# STM32H7S7xx register map
File version: 1.0
Registers are 32-bit, read-write, reset 0x0 unless marked. A register's access mark holds for its fields unless they carry their own. Offsets are from the block's base; [hi:lo] are bit positions; {n}, {i} and the like mark numbered series; 'fields as' and 'values as' point back to an identical list.

## TIM12 — TIM
Base 0x40001800
Same registers: TIM9 0x42004C00
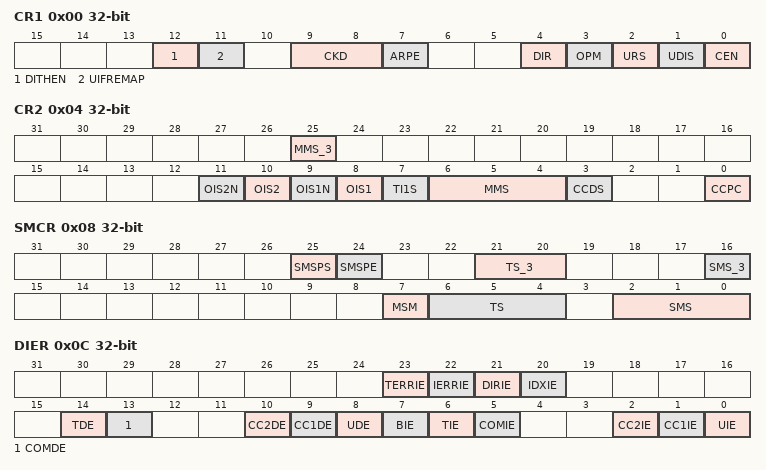
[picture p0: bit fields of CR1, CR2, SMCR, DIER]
0x00 CR1 — TIM control register 1
  [12] DITHEN — Dithering enable
  [11] UIFREMAP — Update interrupt flag remap
  [9:8] CKD — CKD[1:0] bits (clock division)
    0=DIV1 (tDTS=tCK_INT); 1=DIV2 (tDTS=2*tCK_INT); 2=DIV4 (tDTS=4*tCK_INT)
  [7] ARPE — Auto-reload preload enable
  [4] DIR — Direction
    0=UP (Timer counter counts up); 1=DOWN (Timer counter counts down)
  [3] OPM — One pulse mode
    1=SINGLE (Counter stops counting at the next update event); 0=REPETITIVE (Counter is not stopped at update event)
  [2] URS — Update request source
    0=REGULAR (Counter overflow/underflow, Setting the UG bit or Update generation through the slave mode controller generates an update request); 1=COUNTER (Only counter overflow/underflow generates an update request)
  [1] UDIS — Update disable
  [0] CEN — Counter enable
0x04 CR2 — TIM control register 2
  [25] MMS_3 — MMS[3:0] bits (Master Mode Selection)
  [11] OIS2N — Output Idle state 2 (OC2N output)
  [10] OIS2 — Output Idle state 2 (OC2 output)
  [9] OIS1N — Output Idle state 1 (OC1N output)
  [8] OIS1 — Output Idle state 1 (OC1 output)
  [7] TI1S — TI1 Selection
  [6:4] MMS — MMS[3:0] bits (Master Mode Selection)
  [3] CCDS — Capture/Compare DMA Selection
    0=CC (CCx DMA request sent when CCx event occurs); 1=UPDATE (CCx DMA requests sent when update event occurs)
  [0] CCPC — Capture/Compare Preloaded Control
0x08 SMCR — TIM slave mode control register
  [25] SMSPS — SMS preload source
    0=TIMUPDATE (The SMS preload transfer is triggered by the Timer's Update event); 1=INDEX (The SMS preload transfer is triggered by the Index event)
  [24] SMSPE — SMS preload enable
  [21:20] TS_3 — TS[2:0] bits (Trigger selection)
  [16] SMS_3 — SMS[2:0] bits (Slave mode selection)
  [7] MSM — Master/slave mode
  [6:4] TS — TS[2:0] bits (Trigger selection)
  [2:0] SMS — SMS[2:0] bits (Slave mode selection)
0x0C DIER — TIM DMA/interrupt enable register
  [23] TERRIE — Encoder transition error enable
  [22] IERRIE — Encoder index error enable
  [21] DIRIE — Encoder direction change interrupt enable
  [20] IDXIE — Encoder index interrupt enable
  [14] TDE — Trigger DMA request enable
  [13] COMDE — COM DMA request enable
  [10] CC2DE — Capture/Compare 2 DMA request enable
  [9] CC1DE — Capture/Compare 1 DMA request enable
  [8] UDE — Update DMA request enable
  [7] BIE — Break interrupt enable
  [6] TIE — Trigger interrupt enable
  [5] COMIE — COM interrupt enable
  [2] CC2IE — Capture/Compare 2 interrupt enable
  [1] CC1IE — Capture/Compare 1 interrupt enable
  [0] UIE — Update interrupt enable
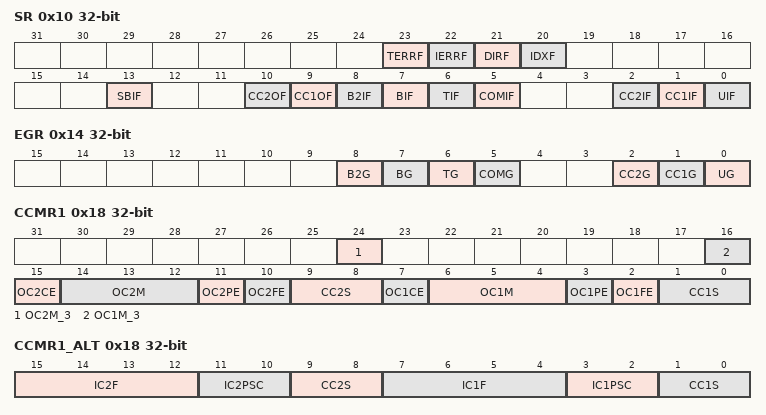
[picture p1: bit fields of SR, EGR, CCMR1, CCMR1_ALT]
0x10 SR — TIM status register
  [23] TERRF — Encoder transition error flag
  [22] IERRF — Encoder index error flag
  [21] DIRF — Encoder direction change interrupt flag
  [20] IDXF — Encoder index interrupt flag
  [13] SBIF — System Break interrupt Flag
  [10] CC2OF — Capture/Compare 2 Overcapture Flag
  [9] CC1OF — Capture/Compare 1 Overcapture Flag
  [8] B2IF — Break 2 interrupt Flag
  [7] BIF — Break interrupt Flag
  [6] TIF — Trigger interrupt Flag
  [5] COMIF — COM interrupt Flag
  [2] CC2IF — Capture/Compare 2 interrupt Flag
  [1] CC1IF — Capture/Compare 1 interrupt Flag
  [0] UIF — Update interrupt Flag
0x14 EGR — TIM event generation register
  [8] B2G — Break 2 Generation
  [7] BG — Break Generation
  [6] TG — Trigger Generation
  [5] COMG — Capture/Compare Control Update Generation
  [2] CC2G — Capture/Compare 2 Generation
  [1] CC1G — Capture/Compare 1 Generation
  [0] UG — Update Generation
0x18 CCMR1 — TIM capture/compare mode register 1
  [24] OC2M_3 — OC2M[2:0] bits (Output Compare 2 Mode)
  [16] OC1M_3 — OC1M[2:0] bits (Output Compare 1 Mode)
  [15] OC2CE — Output Compare 2 Clear Enable
  [14:12] OC2M — OC2M[2:0] bits (Output Compare 2 Mode)
  [11] OC2PE — Output Compare 2 Preload enable
  [10] OC2FE — Output Compare 2 Fast enable
  [9:8] CC2S — CC2S[1:0] bits (Capture/Compare 2 Selection)
  [7] OC1CE — Output Compare 1 Clear Enable
  [6:4] OC1M — OC1M[2:0] bits (Output Compare 1 Mode)
  [3] OC1PE — Output Compare 1 Preload enable
  [2] OC1FE — Output Compare 1 Fast enable
  [1:0] CC1S — CC1S[1:0] bits (Capture/Compare 1 Selection)
0x18 CCMR1_ALT (alternate view of CCMR1) — TIM capture/compare mode register 1
  [15:12] IC2F — IC2F[3:0] bits (Input Capture 2 Filter)
  [11:10] IC2PSC — IC2PSC[1:0] bits (Input Capture 2 Prescaler)
  [9:8] CC2S — CC2S[1:0] bits (Capture/Compare 2 Selection)
  [7:4] IC1F — IC1F[3:0] bits (Input Capture 1 Filter)
  [3:2] IC1PSC — IC1PSC[1:0] bits (Input Capture 1 Prescaler)
  [1:0] CC1S — CC1S[1:0] bits (Capture/Compare 1 Selection)
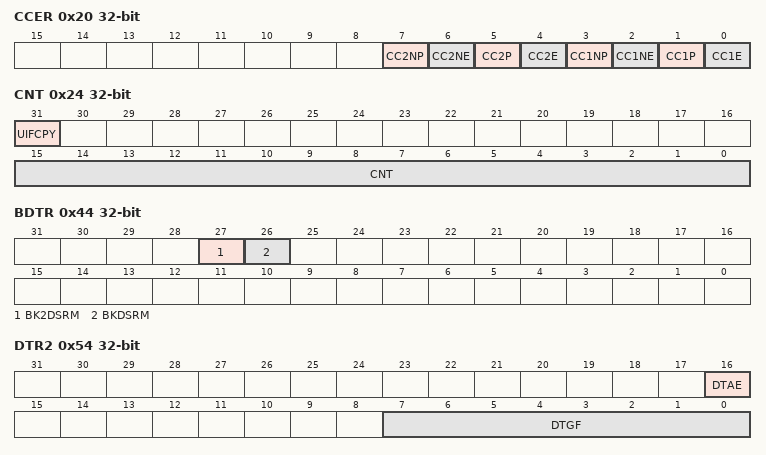
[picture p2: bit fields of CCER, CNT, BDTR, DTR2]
0x20 CCER — TIM capture/compare enable register
  [7] CC2NP — Capture/Compare 2 Complementary output Polarity
  [6] CC2NE — Capture/Compare 2 Complementary output enable
  [5] CC2P — Capture/Compare 2 output Polarity
  [4] CC2E — Capture/Compare 2 output enable
  [3] CC1NP — Capture/Compare 1 Complementary output Polarity
  [2] CC1NE — Capture/Compare 1 Complementary output enable
  [1] CC1P — Capture/Compare 1 output Polarity
  [0] CC1E — Capture/Compare 1 output enable
0x24 CNT — TIM counter register
  [31] UIFCPY — Update interrupt flag copy (if UIFREMAP=1)
  [15:0] CNT — Counter Value
0x28 PSC — TIM prescaler
  [15:0] PSC — Prescaler Value
0x2C ARR — TIM auto-reload register
  [15:0] ARR — Actual auto-reload Value
0x34 CCR1 — TIM capture/compare register 1
  [15:0] CCR1 — Capture/Compare 1 Value
0x38 CCR2 — TIM capture/compare register 2
  [15:0] CCR2 — Capture/Compare 2 Value
0x44 BDTR — TIM break and dead-time register
  [27] BK2DSRM — Break2 disarming/re-arming
  [26] BKDSRM — Break disarming/re-arming
0x54 DTR2 — TIM deadtime register 2
  [16] DTAE — Deadtime asymmetric enable
  [7:0] DTGF — DTGF[7:0] bits (Deadtime falling edge generator setup)
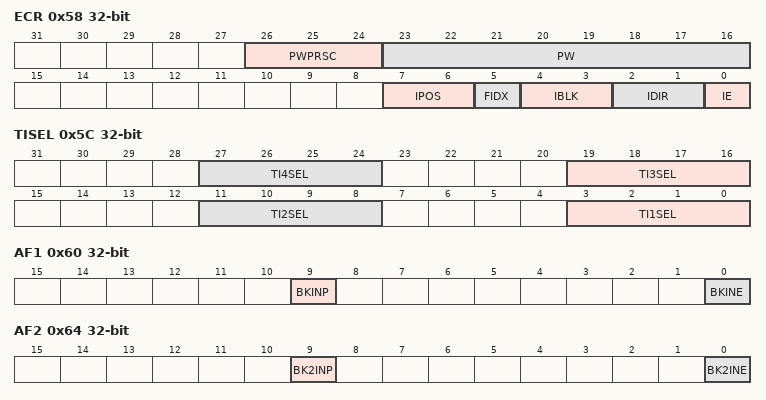
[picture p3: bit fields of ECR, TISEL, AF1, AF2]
0x58 ECR — TIM encoder control register
  [26:24] PWPRSC — PWPRSC[2:0] bits (Pulse width prescaler)
    0=Pulse on compare pulse width prescaler 1; 1=X2 (Pulse on compare pulse width prescaler 2); 2=X4 (Pulse on compare pulse width prescaler 4); 3=X8 (Pulse on compare pulse width prescaler 8); 4=X16 (Pulse on compare pulse width prescaler 16); 5=X32 (Pulse on compare pulse width prescaler 32); 6=X64 (Pulse on compare pulse width prescaler 64); 7=X128 (Pulse on compare pulse width prescaler 128)
  [23:16] PW — PW[7:0] bits (Pulse width)
  [7:6] IPOS — IPOS[1:0] bits (Index positioning)
    0=DOWN_DOWN (Index resets the counter when AB = 00); 1=DOWN_UP (Index resets the counter when AB = 01); 2=UP_DOWN (Index resets the counter when AB = 10); 3=UP_UP (Index resets the counter when AB = 11)
  [5] FIDX — First index enable
  [4:3] IBLK — IBLK[1:0] bits (Index blanking)
    0=ALWAYS (Index always active); 1=TI3 (Index disabled when TI3 input is active, as per CC3P bitfield); 2=TI4 (Index disabled when TI4 input is active, as per CC4P bitfield)
  [2:1] IDIR — IDIR[1:0] bits (Index direction)
    0=UP_DOWN (Index resets the counter whatever the direction); 1=UP (Index resets the counter when up-counting only); 2=DOWN (Index resets the counter when down-counting only)
  [0] IE — Index enable
0x5C TISEL — TIM Input Selection register
  [8n-5:8n-8] TI{n}SEL (n=1..4) — TI{n}SEL[3:0] bits (TIM1 TI{n} SEL)
0x60 AF1 — TIM alternate function option register 1
  [9] BKINP — BRK BKIN input polarity
  [0] BKINE — BRK BKIN input enable
0x64 AF2 — TIM alternate function option register 2
  [9] BK2INP — BRK2 BKIN input polarity
  [0] BK2INE — BRK2 BKIN input enable
0x3E0 DMAR — TIM DMA address for full transfer
  [31:0] DMAB — DMA register for burst accesses

## TIM13 — TIM
Base 0x40001C00
Same registers: TIM14 0x40002000
Registers as TIM12, without CCR2; these are added or differ:
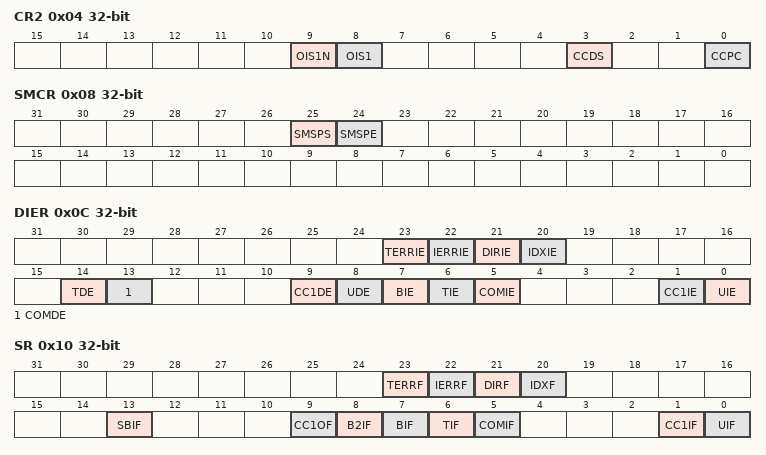
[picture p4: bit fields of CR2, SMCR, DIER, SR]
0x04 CR2 — TIM control register 2
  [9] OIS1N — Output Idle state 1 (OC1N output)
  [8] OIS1 — Output Idle state 1 (OC1 output)
  [3] CCDS — Capture/Compare DMA Selection
    0=CC (CCx DMA request sent when CCx event occurs); 1=UPDATE (CCx DMA requests sent when update event occurs)
  [0] CCPC — Capture/Compare Preloaded Control
0x08 SMCR — TIM slave mode control register
  [25] SMSPS — SMS preload source
    0=TIMUPDATE (The SMS preload transfer is triggered by the Timer's Update event); 1=INDEX (The SMS preload transfer is triggered by the Index event)
  [24] SMSPE — SMS preload enable
0x0C DIER — TIM DMA/interrupt enable register
  [23] TERRIE — Encoder transition error enable
  [22] IERRIE — Encoder index error enable
  [21] DIRIE — Encoder direction change interrupt enable
  [20] IDXIE — Encoder index interrupt enable
  [14] TDE — Trigger DMA request enable
  [13] COMDE — COM DMA request enable
  [9] CC1DE — Capture/Compare 1 DMA request enable
  [8] UDE — Update DMA request enable
  [7] BIE — Break interrupt enable
  [6] TIE — Trigger interrupt enable
  [5] COMIE — COM interrupt enable
  [1] CC1IE — Capture/Compare 1 interrupt enable
  [0] UIE — Update interrupt enable
0x10 SR — TIM status register
  [23] TERRF — Encoder transition error flag
  [22] IERRF — Encoder index error flag
  [21] DIRF — Encoder direction change interrupt flag
  [20] IDXF — Encoder index interrupt flag
  [13] SBIF — System Break interrupt Flag
  [9] CC1OF — Capture/Compare 1 Overcapture Flag
  [8] B2IF — Break 2 interrupt Flag
  [7] BIF — Break interrupt Flag
  [6] TIF — Trigger interrupt Flag
  [5] COMIF — COM interrupt Flag
  [1] CC1IF — Capture/Compare 1 interrupt Flag
  [0] UIF — Update interrupt Flag
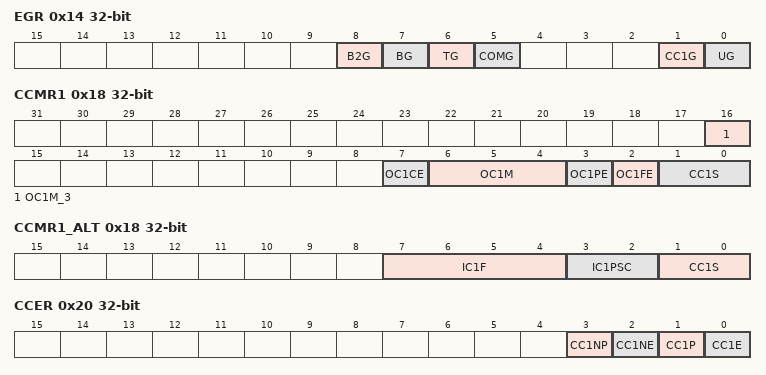
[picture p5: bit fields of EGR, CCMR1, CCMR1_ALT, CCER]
0x14 EGR — TIM event generation register
  [8] B2G — Break 2 Generation
  [7] BG — Break Generation
  [6] TG — Trigger Generation
  [5] COMG — Capture/Compare Control Update Generation
  [1] CC1G — Capture/Compare 1 Generation
  [0] UG — Update Generation
0x18 CCMR1 — TIM capture/compare mode register 1
  [16] OC1M_3 — OC1M[2:0] bits (Output Compare 1 Mode)
  [7] OC1CE — Output Compare 1 Clear Enable
  [6:4] OC1M — OC1M[2:0] bits (Output Compare 1 Mode)
  [3] OC1PE — Output Compare 1 Preload enable
  [2] OC1FE — Output Compare 1 Fast enable
  [1:0] CC1S — CC1S[1:0] bits (Capture/Compare 1 Selection)
0x18 CCMR1_ALT (alternate view of CCMR1) — TIM capture/compare mode register 1
  [7:4] IC1F — IC1F[3:0] bits (Input Capture 1 Filter)
  [3:2] IC1PSC — IC1PSC[1:0] bits (Input Capture 1 Prescaler)
  [1:0] CC1S — CC1S[1:0] bits (Capture/Compare 1 Selection)
0x20 CCER — TIM capture/compare enable register
  [3] CC1NP — Capture/Compare 1 Complementary output Polarity
  [2] CC1NE — Capture/Compare 1 Complementary output enable
  [1] CC1P — Capture/Compare 1 output Polarity
  [0] CC1E — Capture/Compare 1 output enable

## TIM15 — TIM
Base 0x42004000
Registers as TIM12; these are added or differ:
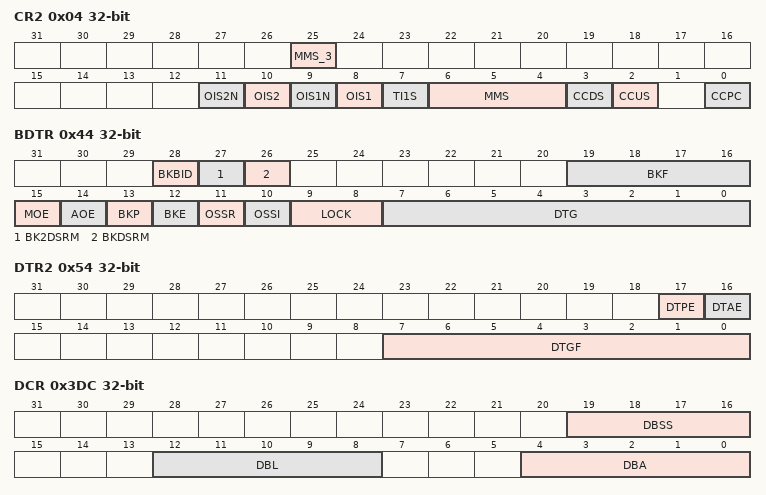
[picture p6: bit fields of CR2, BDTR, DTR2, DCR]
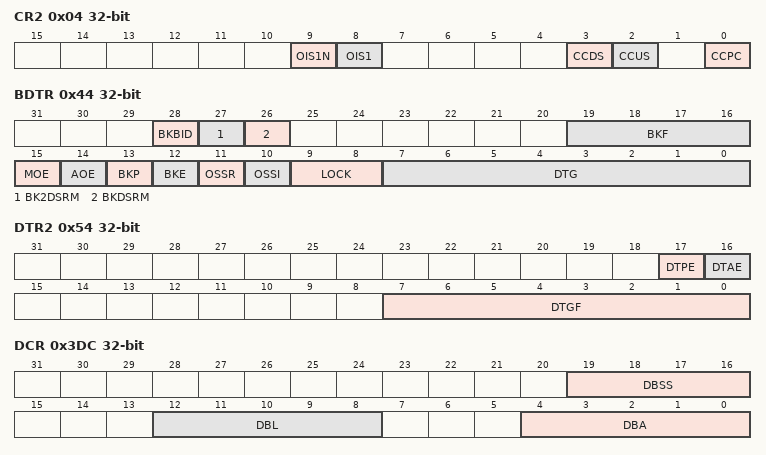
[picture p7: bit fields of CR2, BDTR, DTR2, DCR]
0x04 CR2 — TIM control register 2
  [25] MMS_3 — MMS[3:0] bits (Master Mode Selection)
  [11] OIS2N — Output Idle state 2 (OC2N output)
  [10] OIS2 — Output Idle state 2 (OC2 output)
  [9] OIS1N — Output Idle state 1 (OC1N output)
  [8] OIS1 — Output Idle state 1 (OC1 output)
  [7] TI1S — TI1 Selection
  [6:4] MMS — MMS[3:0] bits (Master Mode Selection)
  [3] CCDS — Capture/Compare DMA Selection
    0=CC (CCx DMA request sent when CCx event occurs); 1=UPDATE (CCx DMA requests sent when update event occurs)
  [2] CCUS — Capture/Compare Control Update Selection
    0=ONLY (Capture/compare control bits are updated by setting the COMG bit only); 1=AND_TRGI (Capture/compare control bits are updated by setting the COMG bit or when a rising edge occurs on trigger input (TRGI))
  [0] CCPC — Capture/Compare Preloaded Control
0x30 RCR — TIM repetition counter register
  [15:0] REP — Repetition Counter Value
0x44 BDTR — TIM break and dead-time register
  [28] BKBID — Break BIDirectional
  [27] BK2DSRM — Break2 disarming/re-arming
  [26] BKDSRM — Break disarming/re-arming
  [19:16] BKF — Break Filter for Break 1
  [15] MOE — Main Output enable
  [14] AOE — Automatic Output enable
  [13] BKP — Break Polarity for Break 1
  [12] BKE — Break enable for Break 1
  [11] OSSR — Off-State Selection for Run mode
  [10] OSSI — Off-State Selection for Idle mode
  [9:8] LOCK — LOCK[1:0] bits (Lock Configuration)
    0=OFF (LOCK OFF - No bit is write protected); 1=LOCKLEVEL_1; 2=LOCKLEVEL_2; 3=LOCKLEVEL_3
  [7:0] DTG — DTG[0:7] bits (Dead-Time Generator set-up)
0x54 DTR2 — TIM deadtime register 2
  [17] DTPE — Deadtime prelaod enable
  [16] DTAE — Deadtime asymmetric enable
  [7:0] DTGF — DTGF[7:0] bits (Deadtime falling edge generator setup)
0x3DC DCR — TIM DMA control register
  [19:16] DBSS — DBSS[19:16] bits (DMA Burst Source Selection)
  [12:8] DBL — DBL[4:0] bits (DMA Burst Length)
  [4:0] DBA — DBA[4:0] bits (DMA Base Address)

## TIM16 — TIM
Base 0x42004400
Same registers: TIM17 0x42004800
Registers as TIM13; these are added or differ:
0x04 CR2 — TIM control register 2
  [9] OIS1N — Output Idle state 1 (OC1N output)
  [8] OIS1 — Output Idle state 1 (OC1 output)
  [3] CCDS — Capture/Compare DMA Selection
    0=CC (CCx DMA request sent when CCx event occurs); 1=UPDATE (CCx DMA requests sent when update event occurs)
  [2] CCUS — Capture/Compare Control Update Selection
    values as TIM15.CR2.CCUS
  [0] CCPC — Capture/Compare Preloaded Control
0x30 RCR — TIM repetition counter register
  [15:0] REP — Repetition Counter Value
0x44 BDTR — TIM break and dead-time register
  fields as TIM15.BDTR
0x54 DTR2 — TIM deadtime register 2
  [17] DTPE — Deadtime prelaod enable
  [16] DTAE — Deadtime asymmetric enable
  [7:0] DTGF — DTGF[7:0] bits (Deadtime falling edge generator setup)
0x3DC DCR — TIM DMA control register
  [19:16] DBSS — DBSS[19:16] bits (DMA Burst Source Selection)
  [12:8] DBL — DBL[4:0] bits (DMA Burst Length)
  [4:0] DBA — DBA[4:0] bits (DMA Base Address)
